# IMC300A register map
Vendor: Infineon; File version: 1.0.0
CPU: CM0 r0p0, little endian, no MPU, no FPU, 2 interrupt priority bits
Registers are 32-bit, read-write, reset 0x0 unless marked. A register's access mark holds for its fields unless they carry their own. Offsets are from the block's base; [hi:lo] are bit positions; {n}, {i} and the like mark numbered series.

## CCU40 — Capture Compare Unit 4 - Unit 0
Base 0x48040000
Same registers: CCU41 0x48044000
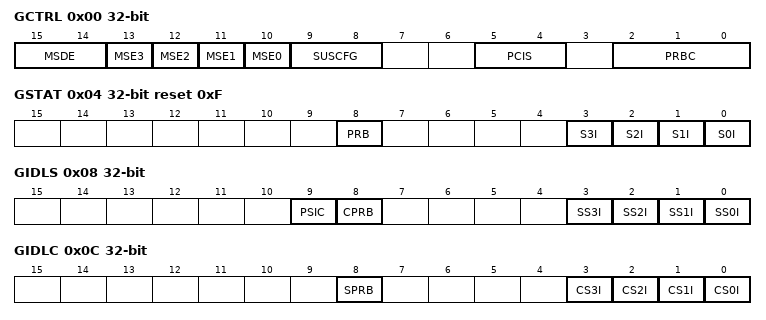
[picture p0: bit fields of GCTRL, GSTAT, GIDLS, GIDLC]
0x00 GCTRL — Global Control Register
  [15:14] MSDE — Multi Channel shadow transfer request configuration
    0=Only the shadow transfer for period and compare values is requested; 1=Shadow transfer for the compare, period and prescaler compare values is requested; 3=Shadow transfer for the compare, period, prescaler and dither compare values is requested
  [n+10] MSE{n} (n=0..3) — Slice {n} Multi Channel shadow transfer enable
    0=Shadow transfer can only be requested by SW; 1=Shadow transfer can be requested via SW and via the CCU4x.MCSS input
  [9:8] SUSCFG — Suspend Mode Configuration
    0=Suspend request ignored. The module never enters in suspend; 1=Stops all the running slices immediately. Safe stop is not applied.; 2=Stops the block immediately and clamps all the outputs to PASSIVE state. Safe stop is applied.; 3=Waits for the roll over of each slice to stop and clamp the slices outputs. Safe stop is applied.
  [5:4] PCIS — Prescaler Input Clock Selection
    0=Module clock; 1=CCU4x.ECLKA; 2=CCU4x.ECLKB; 3=CCU4x.ECLKC
  [2:0] PRBC — Prescaler Clear Configuration
    0=SW only; {v}=GSTATThe register contains the status of the prescaler and each timer slice (idle mode or running)..PRB and prescaler registers are cleared when the Run Bit of CC{v+39} is cleared (v=1..4)
0x04 GSTAT ro reset 0xF — Global Status Register
  [8] PRB — Prescaler Run Bit
    0=Prescaler is stopped; 1=Prescaler is running
  [n] S{n}I (n=0..3) — CC{n+40} IDLE status
    0=Running; 1=Idle
0x08 GIDLS wo — Global Idle Set
  [9] PSIC — Prescaler clear
  [8] CPRB — Prescaler Run Bit Clear
  [n] SS{n}I (n=0..3) — CC{n+40} IDLE mode set
0x0C GIDLC wo — Global Idle Clear
  [8] SPRB — Prescaler Run Bit Set
  [n] CS{n}I (n=0..3) — CC{n+40} IDLE mode clear
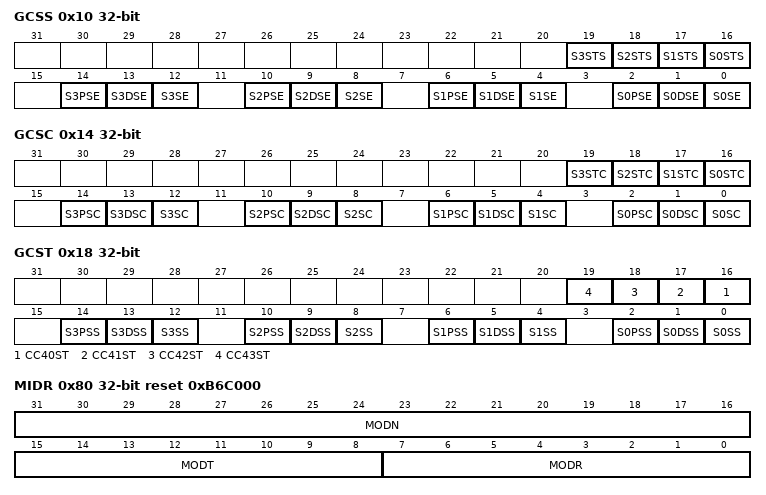
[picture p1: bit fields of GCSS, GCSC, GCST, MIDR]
0x10 GCSS wo — Global Channel Set
  [n+16] S{n}STS (n=0..3) — Slice {n} status bit set
  [4n+2] S{n}PSE (n=0..3) — Slice {n} Prescaler shadow transfer set enable
  [4n+1] S{n}DSE (n=0..3) — Slice {n} Dither shadow transfer set enable
  [4n] S{n}SE (n=0..3) — Slice {n} shadow transfer set enable
0x14 GCSC wo — Global Channel Clear
  [n+16] S{n}STC (n=0..3) — Slice {n} status bit clear
  [4n+2] S{n}PSC (n=0..3) — Slice {n} Prescaler shadow transfer clear
  [4n+1] S{n}DSC (n=0..3) — Slice {n} Dither shadow transfer clear
  [4n] S{n}SC (n=0..3) — Slice {n} shadow transfer clear
0x18 GCST ro — Global Channel Status
  [n-24] CC{n}ST (n=40..43) — Slice {n-40} status bit
  [4n+2] S{n}PSS (n=0..3) — Slice {n} Prescaler shadow transfer status
    0=Prescaler shadow transfer has not been requested; 1=Prescaler shadow transfer has been requested
  [4n+1] S{n}DSS (n=0..3) — Slice {n} Dither shadow transfer status
    0=Dither shadow transfer has not been requested; 1=Dither shadow transfer has been requested
  [4n] S{n}SS (n=0..3) — Slice {n} shadow transfer status
    0=Shadow transfer has not been requested; 1=Shadow transfer has been requested
0x80 MIDR ro reset 0xB6C000 (reset mask 0xFFFFFF00) — Module Identification
  [31:16] MODN — Module Number
  [15:8] MODT — Module Type
  [7:0] MODR — Module Revision

## SHS — Sample and Hold ADC Sequencer
Base 0x48034000
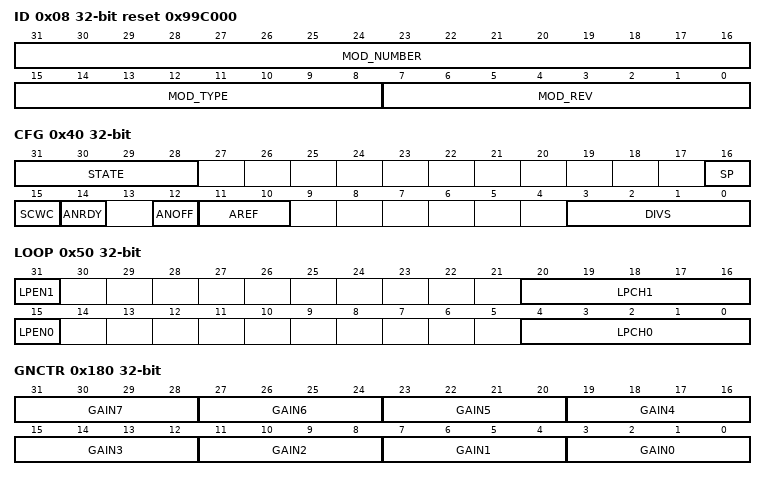
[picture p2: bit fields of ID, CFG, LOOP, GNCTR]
0x08 ID ro reset 0x99C000 (reset mask 0xFFFFFF00) — Module Identification Register
  [31:16] MOD_NUMBER — Module Number
  [15:8] MOD_TYPE — Module Type
  [7:0] MOD_REV — Module Revision
0x40 CFG access per field — Configuration Register
  [31:28] STATE ro — Current State of Sequencer
    0=Idle; 1=Offset calibration active; 2=Gain calibration active; 3=Startup calibration active; 8=Stepper process active
  [16] SP ro — Sample Pending
    0=No sample pending; 1=Sample pending
  [15] SCWC wo — Write Control for SHS Configuration
    0=No write access to SHS configuration; 1=Bitfields ANOFF, AREF, DIVS can be written
  [14] ANRDY ro — Analog Converter Ready
    0=Converter is in power-down mode; 1=Converter is operable
  [12] ANOFF rw — Analog Converter Power Down Force
    0=Converter controlled by bitfields ANONS (digital control block); 1=Converter is permanently off
  [11:10] AREF rw — Analog Calbration Reference Voltage Selection
    0=External reference, upper supply range; 2=Internal reference, upper supply range; 3=Internal reference, lower supply range
  [3:0] DIVS rw — Divider Factor for the SHS Clock
    0=fSH = fCONV / 1; 1=fSH = fCONV / 2; 7=fSH = fCONV / 8
0x50 LOOP — SD Loop Control Register
  [31] LPEN1 — Loop 1 Enable
    0=Off: standard operation; 1=ON: sigma-delta-loop is active
  [20:16] LPCH1 — Loop 1 Channel
  [15] LPEN0 — Loop 0 Enable
    0=Off: standard operation; 1=ON: sigma-delta-loop is active
  [4:0] LPCH0 — Loop 0 Channel
0x180 GNCTR — Gain Control Register
  [all] fields
    0=Gain factor = 1; 1=Gain factor = 3; 2=Gain factor = 6; 3=Gain factor = 12
  [4n+3:4n] GAIN{n} (n=0..7) — Gain Control {n}
